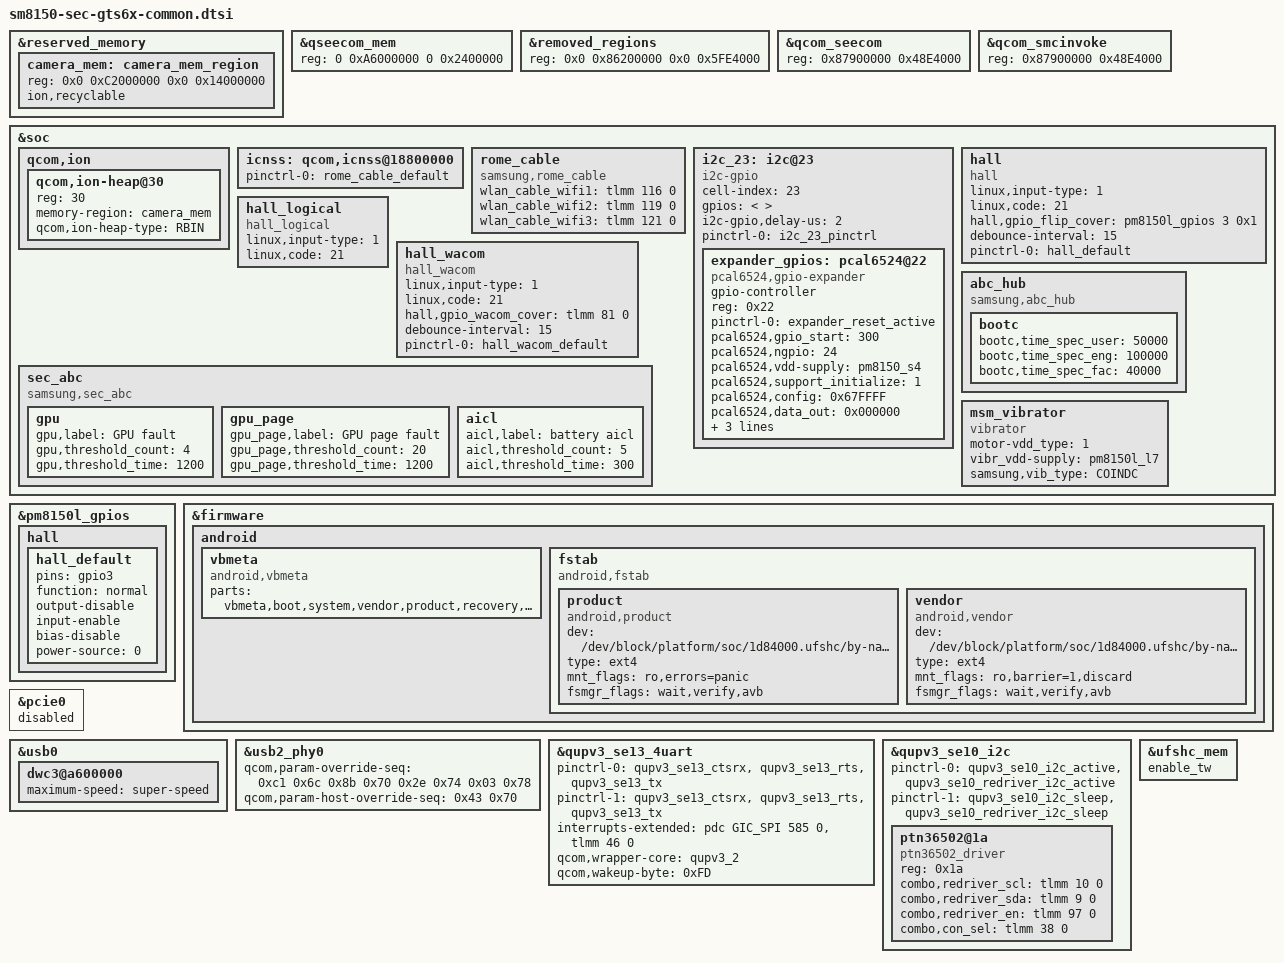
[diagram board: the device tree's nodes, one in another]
/* Copyright (c) 2016-2017, The Linux Foundation. All rights reserved.
 *
 * This program is free software; you can redistribute it and/or modify
 * it under the terms of the GNU General Public License version 2 and
 * only version 2 as published by the Free Software Foundation.
 *
 * This program is distributed in the hope that it will be useful,
 * but WITHOUT ANY WARRANTY; without even the implied warranty of
 * MERCHANTABILITY or FITNESS FOR A PARTICULAR PURPOSE.  See the
 * GNU General Public License for more details.
 */

#include "sm8150-sec-gts6l-audio.dtsi"
#include "../../../../../drivers/motor/tuning/beyond0qlte_motor_tuning.dtsi"
#include "sm8150-sec-gts6x-input-common.dtsi"
#include <dt-bindings/phy/qcom,sm8150-qmp-usb3.h>

&reserved_memory {
	camera_mem: camera_mem_region {
		reg = <0x0 0xC2000000 0x0 0x14000000>;
		ion,recyclable;
	};
};

&qseecom_mem {
	reg = <0 0xA6000000 0 0x2400000>;
};

/* TZapp region */
&removed_regions {
	reg = <0x0 0x86200000 0x0 0x5FE4000>;
};
/* only for compatibility, not used for qcom,appsbl-qseecom-support */
&qcom_seecom {
	reg = <0x87900000 0x48E4000>;
};
/* only for compatibility, there is no handling routine for reg in SMCinvoke driver */
&qcom_smcinvoke {
	reg = <0x87900000 0x48E4000>;
};

&soc {
	qcom,ion {
		qcom,ion-heap@30 { /* CAMERA HEAP  */
			reg = <30>;
			memory-region = <&camera_mem>;
			qcom,ion-heap-type = "RBIN";
		};
	};
	icnss: qcom,icnss@18800000 {
		pinctrl-names = "default";
		pinctrl-0 = <&rome_cable_default>;
	};
	rome_cable {
		compatible = "samsung,rome_cable";
		wlan_cable_wifi1 = <&tlmm 116 0>;
		wlan_cable_wifi2 = <&tlmm 119 0>;
		wlan_cable_wifi3 = <&tlmm 121 0>;
		status = "ok";
	};
};

&pm8150l_gpios {
	hall {
		hall_default: hall_default {
			pins = "gpio3";
			function = "normal";
			output-disable;
			input-enable;
			bias-disable;
			power-source = <0>;
		};
	};
};

&soc {
	i2c_23: i2c@23 {
		status = "ok";

		cell-index = <23>;
		compatible = "i2c-gpio";
		gpios = </*&tlmm 21 0*/	/* EXPANDER_I2C_SDA_1P8 */
			 /*&tlmm 22 0*/	/* EXPANDER_I2C_SCL_1P8 */
		>;
		i2c-gpio,delay-us = <2>;
		#address-cells = <1>;
		#size-cells = <0>;

		pinctrl-names = "default";
		pinctrl-0 = <&i2c_23_pinctrl>;

		expander_gpios: pcal6524@22 {
			compatible = "pcal6524,gpio-expander";
			gpio-controller;
			#gpio-cells = <2>;
			reg = <0x22>;
			pinctrl-names = "expander_reset_setting";
			pinctrl-0 = <&expander_reset_active>;
			pcal6524,gpio_start = <300>;
			pcal6524,ngpio = <24>;
			/*pcal6524,reset-gpio = <&tlmm 29 0>;*/
			pcal6524,vdd-supply = <&pm8150_s4>;
			pcal6524,support_initialize = <1>;
			/* config, 24 ~ 0, 1bit configure[1:input, 0:output]*/
			pcal6524,config = <0x67FFFF>;    /* P2[01100111] P1[11111111] P0[11111111] */
			/* data_out, 24 ~ 0, 1bit configure[1:high, 0:low]*/
			pcal6524,data_out = <0x000000>;  /* P2[00000000] P1[00000000] P0[00000000] */
			/* pull_reg, 8 ~ 0, 2bit configure[00:no_pull, 01:pull_down, 10:pull_up, 11:not used] */
			pcal6524,pull_reg_p0 = <0x0000>; /* 00 00 00 00 / 00 00 00 00 */
			pcal6524,pull_reg_p1 = <0x0000>; /* 00 00 00 00 / 00 00 00 00 */
			pcal6524,pull_reg_p2 = <0x0000>; /* 00 00 00 00 / 00 00 00 00 */
		};
	};

        hall {
                status = "okay";
                compatible = "hall";
                linux,input-type = <1>;
                linux,code = <21>;
                hall,gpio_flip_cover = <&pm8150l_gpios 3 0x1>;
                debounce-interval = <15>;
		pinctrl-names = "default";
	        pinctrl-0 = <&hall_default>;
        };

        hall_logical {
                status = "okay";
                compatible = "hall_logical";
                linux,input-type = <1>;
                linux,code = <21>;
        };

	hall_wacom {
                status = "okay";
                compatible = "hall_wacom";
                linux,input-type = <1>;
                linux,code = <21>;
                hall,gpio_wacom_cover = <&tlmm 81 0>;
                debounce-interval = <15>;
		pinctrl-names = "default";
	        pinctrl-0 = <&hall_wacom_default>;
        };

	sec_abc {
		compatible = "samsung,sec_abc";
		status = "okay";

		gpu {
			gpu,label="GPU fault";
			gpu,threshold_count=<4>;
			gpu,threshold_time=<1200>;
		};
		gpu_page {
			gpu_page,label="GPU page fault";
			gpu_page,threshold_count=<20>;
			gpu_page,threshold_time=<1200>;
		};
		aicl {
			aicl,label="battery aicl";
			aicl,threshold_count=<5>;
			aicl,threshold_time=<300>;
		};
	};

	abc_hub {
		compatible = "samsung,abc_hub";
		status = "okay";

		bootc {
			bootc,time_spec_user = <50000>; /* user binary user build */
			bootc,time_spec_eng = <100000>; /* user binary eng build */
			bootc,time_spec_fac = <40000>; /* factory binary */
		};

	};

	msm_vibrator {
		compatible = "vibrator";
		motor-vdd_type = <1>; /* 0: gpio, 1: pmic */
		vibr_vdd-supply = <&pm8150l_l7>;
		samsung,vib_type = "COINDC";
	};
};

&firmware {
	android {
		vbmeta {
			compatible = "android,vbmeta";
			parts = "vbmeta,boot,system,vendor,product,recovery,dtbo,abl,xbl,tz,hyp";
		};
		fstab {
			compatible = "android,fstab";
			product {
				compatible = "android,product";
				/* dev = "/dev/block/bootdevice/by-name/product"; */
				dev = "/dev/block/platform/soc/1d84000.ufshc/by-name/product";
				type = "ext4";
				mnt_flags = "ro,errors=panic";
				fsmgr_flags = "wait,verify,avb";
			};
			vendor {
				compatible = "android,vendor";
				/*dev = "/dev/block/bootdevice/by-name/vendor";*/
				dev = "/dev/block/platform/soc/1d84000.ufshc/by-name/vendor";
				type = "ext4";
				mnt_flags = "ro,barrier=1,discard";
				fsmgr_flags = "wait,verify,avb";
			};
		};
	};
};

&pcie0 {
	status = "disabled";
};

&usb0 {
	dwc3@a600000 {
		maximum-speed = "super-speed";
	};
};

&usb2_phy0 {
	qcom,param-override-seq =
		<0xc1 0x6c
		 0x8b 0x70
		 0x2e 0x74
		 0x03 0x78>;
	qcom,param-host-override-seq =
		<0x43 0x70>;
};

&qupv3_se13_4uart {
	pinctrl-0 = <&qupv3_se13_ctsrx>, <&qupv3_se13_rts>,
					<&qupv3_se13_tx>;
	pinctrl-1 = <&qupv3_se13_ctsrx>, <&qupv3_se13_rts>,
					<&qupv3_se13_tx>;
	interrupts-extended = <&pdc GIC_SPI 585 0>,
			<&tlmm 46 0>;
	qcom,wrapper-core = <&qupv3_2>;
	qcom,wakeup-byte = <0xFD>;
	status = "ok";
};

&qupv3_se10_i2c {
	status = "ok";

	pinctrl-names = "default", "sleep";
	pinctrl-0 = <&qupv3_se10_i2c_active &qupv3_se10_redriver_i2c_active>;
	pinctrl-1 = <&qupv3_se10_i2c_sleep &qupv3_se10_redriver_i2c_sleep>;

	ptn36502@1a {
		compatible = "ptn36502_driver";
		reg = <0x1a>;
		combo,redriver_scl = <&tlmm 10 0>;
		combo,redriver_sda = <&tlmm 9 0>;
		combo,redriver_en = <&tlmm 97 0>;
		combo,con_sel = <&tlmm 38 0>;
	};
};

&ufshc_mem {
	enable_tw;
};
